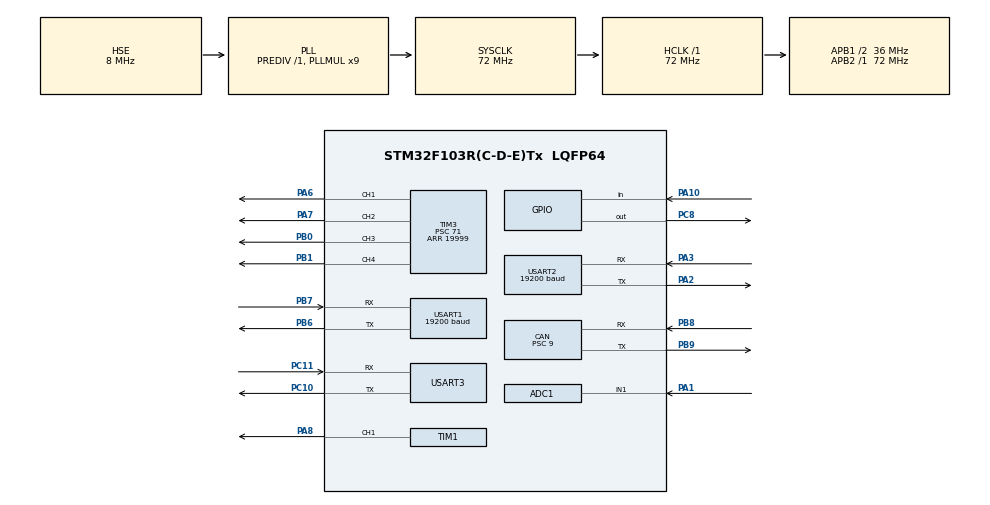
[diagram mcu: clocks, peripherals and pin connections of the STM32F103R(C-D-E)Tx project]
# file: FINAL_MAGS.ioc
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ADC1.Channel-0\#ChannelRegularConversion=ADC_CHANNEL_1
ADC1.ContinuousConvMode=DISABLE
ADC1.DataAlign=ADC_DATAALIGN_RIGHT
ADC1.DiscontinuousConvMode=DISABLE
ADC1.EnableAnalogWatchDog=false
ADC1.EnableRegularConversion=ENABLE
ADC1.ExternalTrigConv=ADC_SOFTWARE_START
ADC1.InjNumberOfConversion=0
ADC1.NbrOfConversion=1
ADC1.NbrOfConversionFlag=1
ADC1.Rank-0\#ChannelRegularConversion=1
ADC1.SamplingTime-0\#ChannelRegularConversion=ADC_SAMPLETIME_239CYCLES_5
ADC1.ScanConvMode=ADC_SCAN_DISABLE
ADC1.master=1
CAN.BS1=CAN_BS1_6TQ
CAN.CalculateTimeBit=750
CAN.CalculateTimeQuantum=250.0
CAN.Prescaler=9
Mcu.Family=STM32F1
Mcu.Name=STM32F103R(C-D-E)Tx
Mcu.Package=LQFP64
NVIC.PriorityGroup=NVIC_PRIORITYGROUP_4
NVIC.TIM7_IRQn=true\:0\:0\:false\:false\:true\:true
NVIC.USART1_IRQn=true\:0\:0\:false\:false\:true\:true
NVIC.USART2_IRQn=true\:0\:0\:false\:false\:true\:true
NVIC.USB_HP_CAN1_TX_IRQn=true\:0\:0\:false\:false\:true\:true
NVIC.USB_LP_CAN1_RX0_IRQn=true\:0\:0\:false\:false\:true\:true
PA1.Signal=ADCx_IN1
PA10.Signal=GPIO_Input
PA2.Mode=Asynchronous
PA2.Signal=USART2_TX
PA3.Mode=Asynchronous
PA3.Signal=USART2_RX
PA6.Signal=S_TIM3_CH1
PA7.Signal=S_TIM3_CH2
PA8.Signal=S_TIM1_CH1
PB0.Signal=S_TIM3_CH3
PB1.Signal=S_TIM3_CH4
PB6.Mode=Asynchronous
PB6.Signal=USART1_TX
PB7.Mode=Asynchronous
PB7.Signal=USART1_RX
PB8.Mode=Master
PB8.Signal=CAN_RX
PB9.Mode=Master
PB9.Signal=CAN_TX
PC10.Mode=Asynchronous
PC10.Signal=USART3_TX
PC11.Mode=Asynchronous
PC11.Signal=USART3_RX
PC8.Signal=GPIO_Output
PD0-OSC_IN.Mode=HSE-External-Oscillator
PD0-OSC_IN.Signal=RCC_OSC_IN
PD1-OSC_OUT.Mode=HSE-External-Oscillator
PD1-OSC_OUT.Signal=RCC_OSC_OUT
ProjectManager.HeapSize=0x200
ProjectManager.StackSize=0x400
ProjectManager.TargetToolchain=EWARM
RCC.ADCPresc=RCC_ADCPCLK2_DIV6
RCC.AHBFreq_Value=72000000
RCC.APB1CLKDivider=RCC_HCLK_DIV2
RCC.APB1Freq_Value=36000000
RCC.APB1TimFreq_Value=72000000
RCC.APB2Freq_Value=72000000
RCC.APB2TimFreq_Value=72000000
RCC.HCLKFreq_Value=72000000
RCC.PLLMUL=RCC_PLL_MUL9
RCC.PLLSourceVirtual=RCC_PLLSOURCE_HSE
RCC.SYSCLKFreq_VALUE=72000000
RCC.SYSCLKSource=RCC_SYSCLKSOURCE_PLLCLK
RCC.USBFreq_Value=72000000
SH.ADCx_IN1.0=ADC1_IN1,IN1
SH.S_TIM1_CH1.0=TIM1_CH1,PWM Generation1 CH1
SH.S_TIM3_CH1.0=TIM3_CH1,PWM Generation1 CH1
SH.S_TIM3_CH2.0=TIM3_CH2,PWM Generation2 CH2
SH.S_TIM3_CH3.0=TIM3_CH3,PWM Generation3 CH3
SH.S_TIM3_CH4.0=TIM3_CH4,PWM Generation4 CH4
TIM1.Channel-PWM\ Generation1\ CH1=TIM_CHANNEL_1
TIM1.Period=19999
TIM1.Prescaler=71
TIM3.Channel-PWM\ Generation1\ CH1=TIM_CHANNEL_1
TIM3.Channel-PWM\ Generation2\ CH2=TIM_CHANNEL_2
TIM3.Channel-PWM\ Generation3\ CH3=TIM_CHANNEL_3
TIM3.Channel-PWM\ Generation4\ CH4=TIM_CHANNEL_4
TIM3.Period=19999
TIM3.Prescaler=71
TIM7.Period=9999
TIM7.Prescaler=7199
USART1.BaudRate=19200
USART1.VirtualMode=VM_ASYNC
USART2.BaudRate=19200
USART2.VirtualMode=VM_ASYNC
USART3.VirtualMode=VM_ASYNC
VP_SYS_VS_ND.Mode=No_Debug
VP_TIM1_VS_ClockSourceINT.Mode=Internal
VP_TIM3_VS_ClockSourceINT.Mode=Internal
VP_TIM7_VS_ClockSourceINT.Mode=Enable_Timer
board=custom

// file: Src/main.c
/**
  ******************************************************************************
  * @file           : main.c
  * @brief          : Main program body
  ******************************************************************************
  ** This notice applies to any and all portions of this file
  * that are not between comment pairs USER CODE BEGIN and
  * USER CODE END. Other portions of this file, whether
  * inserted by the user or by software development tools
  * are owned by their respective copyright owners.
  *
  * COPYRIGHT(c) 2018 STMicroelectronics
  *
  * Redistribution and use in source and binary forms, with or without modification,
  * are permitted provided that the following conditions are met:
  *   1. Redistributions of source code must retain the above copyright notice,
  *      this list of conditions and the following disclaimer.
  *   2. Redistributions in binary form must reproduce the above copyright notice,
  *      this list of conditions and the following disclaimer in the documentation
  *      and/or other materials provided with the distribution.
  *   3. Neither the name of STMicroelectronics nor the names of its contributors
  *      may be used to endorse or promote products derived from this software
  *      without specific prior written permission.
  *
  * THIS SOFTWARE IS PROVIDED BY THE COPYRIGHT HOLDERS AND CONTRIBUTORS "AS IS"
  * AND ANY EXPRESS OR IMPLIED WARRANTIES, INCLUDING, BUT NOT LIMITED TO, THE
  * IMPLIED WARRANTIES OF MERCHANTABILITY AND FITNESS FOR A PARTICULAR PURPOSE ARE
  * DISCLAIMED. IN NO EVENT SHALL THE COPYRIGHT HOLDER OR CONTRIBUTORS BE LIABLE
  * FOR ANY DIRECT, INDIRECT, INCIDENTAL, SPECIAL, EXEMPLARY, OR CONSEQUENTIAL
  * DAMAGES (INCLUDING, BUT NOT LIMITED TO, PROCUREMENT OF SUBSTITUTE GOODS OR
  * SERVICES; LOSS OF USE, DATA, OR PROFITS; OR BUSINESS INTERRUPTION) HOWEVER
  * CAUSED AND ON ANY THEORY OF LIABILITY, WHETHER IN CONTRACT, STRICT LIABILITY,
  * OR TORT (INCLUDING NEGLIGENCE OR OTHERWISE) ARISING IN ANY WAY OUT OF THE USE
  * OF THIS SOFTWARE, EVEN IF ADVISED OF THE POSSIBILITY OF SUCH DAMAGE.
  *
  ******************************************************************************
  */
#include "main.h"
#include "stm32f1xx_hal.h"

/* USER CODE BEGIN Includes */
#include "total.h"
#include <string.h>
#include <stdio.h>
#include <stdlib.h>
#include <math.h>
#define PI 3.141592
/* USER CODE END Includes */

ADC_HandleTypeDef hadc1;

CAN_HandleTypeDef hcan;

TIM_HandleTypeDef htim1;
TIM_HandleTypeDef htim3;
TIM_HandleTypeDef htim7;

UART_HandleTypeDef huart1;
UART_HandleTypeDef huart2;
UART_HandleTypeDef huart3;

/* USER CODE BEGIN PV */
/* Private variables ---------------------------------------------------------*/
uint8_t buffer[1];//store uart1 rf received value
int tim_sec,servo=1500,bat_value;//In timer interrupt variation to update NOW latitude,longtitude;
double Al,Dl,Aa,Da,yaw_1;//GPS_Auto_sailing variation
extern int G_dir,M_spd,M_dir,stop_flag,flag_4,flag_5,flag_6;
double Dlatitude,Dlongtitude;//GPS_Auto_sailing GPS arrive location
extern uint8_t BUF[500];//GPS_BUF
extern uint8_t GPSBUF[500];
extern uint8_t rx_buf[1];

int n = 0;

uint8_t DGPS[19];
uint8_t Dlat[9];
uint8_t Dlong[10];
uint8_t DLAT[9];
uint8_t DLONG[10];
uint8_t tmp[19];
/* USER CODE END PV */

void SystemClock_Config(void);
static void MX_GPIO_Init(void);
static void MX_USART1_UART_Init(void);
static void MX_USART2_UART_Init(void);
static void MX_ADC1_Init(void);
static void MX_TIM3_Init(void);
static void MX_TIM1_Init(void);
static void MX_USART3_UART_Init(void);
static void MX_CAN_Init(void);
static void MX_TIM7_Init(void);

void HAL_TIM_MspPostInit(TIM_HandleTypeDef *htim);

/* USER CODE BEGIN PFP */
/* Private function prototypes -----------------------------------------------*/

/* USER CODE END PFP */

/* USER CODE BEGIN 0 */
int fputc(int ch, FILE *f)
{
    uint8_t temp[1]={ch};

    HAL_UART_Transmit(&huart1, temp, 1, 1000);

  return(ch);
}

void reset_state()
{
        //moter speed step1
        TIM3->CCR3=1575;
        HAL_Delay(10);
        //moter servo center
        TIM3->CCR1=servo;
        HAL_Delay(10);
        //gimbal direction center
        TIM1->CCR1=1500;
        HAL_Delay(10);
        //direction , speed value reset
        G_dir=4;
        M_spd=2;
        M_dir=5;
	servo=1500;
}

void HAL_TIM_PeriodElapsedCallback(TIM_HandleTypeDef *htim)
{
    if(htim->Instance==TIM7)
    {
        if(flag_4==1)
          tim_sec++;

        bat_value++;
        if(bat_value>60)
        {
             bat_value=0;
             Bat_check(&hadc1);
        }
    }
}

/* USER CODE END 0 */

int main(void)
{
  /* USER CODE BEGIN 1 */
  double A_ang,D_ang;
  double error;
  double p_gain=0.3;
  /* USER CODE END 1 */

  /* MCU Configuration----------------------------------------------------------*/

  /* Reset of all peripherals, Initializes the Flash interface and the Systick. */
  HAL_Init();

  /* Configure the system clock */
  SystemClock_Config();

  /* Initialize all configured peripherals */
  MX_GPIO_Init();
  MX_USART1_UART_Init();
  MX_USART2_UART_Init();
  MX_ADC1_Init();
  MX_TIM3_Init();
  MX_TIM1_Init();
  MX_USART3_UART_Init();
  MX_CAN_Init();
  MX_TIM7_Init();
  /* USER CODE BEGIN 2 */
  HAL_TIM_PWM_Start(&htim3,TIM_CHANNEL_3);      //main moter pwm start_TIM3_CH3
  HAL_TIM_PWM_Start(&htim3,TIM_CHANNEL_2);      //water moter pwm start_TIM3_CH2
  HAL_TIM_PWM_Start(&htim3,TIM_CHANNEL_1);      //main servo pwm start_TIM3_CH1
  HAL_TIM_PWM_Start(&htim1,TIM_CHANNEL_1);      //gimbal servo pwm start_TIM1_CH1
  HAL_TIM_Base_Start_IT(&htim7);//tim intrrupt start
  uint8_t p_gain_cont[7]={0,};
  /* USER CODE END 2 */

  /* Infinite loop */
  /* USER CODE BEGIN WHILE */
  while (1)
  {

    HAL_UART_Receive_IT(&huart1,buffer, 1);
    water_mot_con(GPIOA, GPIO_PIN_10);
    if((HAL_UART_Receive(&huart2,tmp,19, 500)==HAL_OK))
    {
      for(int i=0;i<19;i++)
      {
        if(i==2||i==12)
          tmp[i]=tmp[i];
        else
        tmp[i] = tmp[i]-48;
      }
        Da=tmp[0]*10 + tmp[1] + tmp[3]*0.1 + tmp[4]*0.01 + tmp[5]*0.001 + tmp[6]*0.0001 + tmp[7]*0.00001 + tmp[8]*0.000001;
        Dl=tmp[9]*100 + tmp[10]*10 + tmp[11] + tmp[13]*0.1 + tmp[14]*0.01 + tmp[15]*0.001 + tmp[16]*0.0001+ tmp[17]*0.00001 + tmp[18]*0.000001;
        printf("g%lf%lf",Da,Dl);

       for(int i=0;i<19;i++)
      {
        tmp[i] = 0;
      }
    }

    double SD = Yaw_Parse(&huart1,&huart3);

    if(flag_6==1)
    {

        int tmp[7]={0,};
        while(1)
        {
                if((HAL_UART_Receive(&huart1,p_gain_cont, 7, 100000)==HAL_OK))
                {
                    for(int i=0; i<7; i++)
                    {
                      if(i==1)
                        tmp[i]=tmp[i];
                      else
                        tmp[i]=p_gain_cont[i]-48;
                    }
                    p_gain=tmp[0]+tmp[2]*0.1+tmp[3]*0.01+tmp[4]*0.001+tmp[5]*0.0001+tmp[6]*0.00001;
                    flag_6=0;
                    printf("%lf",p_gain);
                    break;
                }
        }
    }
    //receive arrive gps location and start gps chashing
    if(flag_4==1)
      {

        while(1)
        {
                if((HAL_UART_Receive(&huart1, DGPS, 19, 100000)==HAL_OK))
                {
                    for(int i=0;i<9;i++)
                    {
                      Dlat[i] = DGPS[i];
                      DLAT[i] = Dlat[i]-48;
                    }
                    for(int i=0;i<10;i++)
                    {
                      Dlong[i] = DGPS[9+i];
                      DLONG[i] = Dlong[i]-48;
                    }
                      Dlatitude = DLAT[0]*10 + DLAT[1] + DLAT[3]*0.1 + DLAT[4]*0.01 + DLAT[5]*0.001 + DLAT[6]*0.0001 + DLAT[7]*0.00001 + DLAT[8]*0.000001;
                      Dlongtitude = DLONG[0]*100 + DLONG[1]*10 + DLONG[2] + DLONG[4]*0.1 + DLONG[5]*0.01 + DLONG[6]*0.001 + DLONG[7]*0.0001+ DLONG[8]*0.00001 + DLONG[9]*0.000001;
                      break;
                }
        }
            while(1)
            {
              TIM3->CCR3=1550;
              while(1)
              {
                if((HAL_UART_Receive(&huart2,tmp,19, 500)==HAL_OK))
                {
                  for(int i=0;i<19;i++)
                  {
                    if(i==2||i==12)
                      tmp[i]=tmp[i];
                    else
                    tmp[i] = tmp[i]-48;
                  }
                    Da=tmp[0]*10 + tmp[1] + tmp[3]*0.1 + tmp[4]*0.01 + tmp[5]*0.001 + tmp[6]*0.0001 + tmp[7]*0.00001 + tmp[8]*0.000001;
                    Dl=tmp[9]*100 + tmp[10]*10 + tmp[11] + tmp[13]*0.1 + tmp[14]*0.01 + tmp[15]*0.001 + tmp[16]*0.0001+ tmp[17]*0.00001 + tmp[18]*0.000001;
                    printf("g%lf%lf",Da,Dl);

                   for(int i=0;i<19;i++)
                  {
                    tmp[i] = 0;
                  }
                    break;
                }
              }
                Al=Dlongtitude;
                Aa=Dlatitude;
                A_ang=atan2(Al-Dl,Aa-Da)*(double)(180/PI);
                reset_state();
                flag_5=1;

                while(1)
                {
                    HAL_UART_Receive_IT(&huart1,buffer, 1);

                    while(1)
                    {
                        if((HAL_UART_Receive(&huart2,tmp,19, 500)==HAL_OK))
                        {
                          for(int i=0;i<19;i++)
                          {
                            if(i==2||i==12)
                              tmp[i]=tmp[i];
                            else
                            tmp[i] = tmp[i]-48;
                          }
                            Da=tmp[0]*10 + tmp[1] + tmp[3]*0.1 + tmp[4]*0.01 + tmp[5]*0.001 + tmp[6]*0.0001 + tmp[7]*0.00001 + tmp[8]*0.000001;
                            Dl=tmp[9]*100 + tmp[10]*10 + tmp[11] + tmp[13]*0.1 + tmp[14]*0.01 + tmp[15]*0.001 + tmp[16]*0.0001+ tmp[17]*0.00001 + tmp[18]*0.000001;
                            printf("g%lf%lf",Da,Dl);
                           for(int i=0;i<19;i++)
                          {
                            tmp[i] = 0;
                          }
                          break;
                        }
                    }

                    if(tim_sec>=3)
                    {
                      A_ang=atan2(Al-Dl,Aa-Da)*(double)(180/PI);
                      tim_sec=0;
                    }

                    D_ang=Yaw_Parse(&huart1,&huart3);
                    error=A_ang-D_ang;
                    error=error*p_gain;
                    //Convert to Min Angle
                    if(error<=-180)
                        error+=360;
                    else if(error>180)
                        error-=360;
                    //servo timer value must integer
                    servo=(int)(servo+10*error);
                    //limit servo degree value
                    if(servo>=1990)
                    {
                        servo=1990;
                        TIM3->CCR1=1990;
                    }
                    else if(servo<=1010)
                    {
                        servo=1010;
                        TIM3->CCR1=1010;
                    }
                    else
                        TIM3->CCR1=servo;
                    //distance a from d
                    if(((fabs(Al-Dl)<=0.0001)&&(fabs(Aa-Da)<=0.0001))||(stop_flag!=0))//오차값 정하고 1대신 넣기
                    {
                        break;
                    }
                }
                flag_5=0;
                reset_state();
                stop_flag=0;
                flag_4=0;
                break;
            }
  /* USER CODE END WHILE */
  }
  }
}

void SystemClock_Config(void)
{

  RCC_OscInitTypeDef RCC_OscInitStruct;
  RCC_ClkInitTypeDef RCC_ClkInitStruct;
  RCC_PeriphCLKInitTypeDef PeriphClkInit;

    /**Initializes the CPU, AHB and APB busses clocks
    */
  RCC_OscInitStruct.OscillatorType = RCC_OSCILLATORTYPE_HSE;
  RCC_OscInitStruct.HSEState = RCC_HSE_ON;
  RCC_OscInitStruct.HSEPredivValue = RCC_HSE_PREDIV_DIV1;
  RCC_OscInitStruct.HSIState = RCC_HSI_ON;
  RCC_OscInitStruct.PLL.PLLState = RCC_PLL_ON;
  RCC_OscInitStruct.PLL.PLLSource = RCC_PLLSOURCE_HSE;
  RCC_OscInitStruct.PLL.PLLMUL = RCC_PLL_MUL9;
  if (HAL_RCC_OscConfig(&RCC_OscInitStruct) != HAL_OK)
  {
    _Error_Handler(__FILE__, __LINE__);
  }

    /**Initializes the CPU, AHB and APB busses clocks
    */
  RCC_ClkInitStruct.ClockType = RCC_CLOCKTYPE_HCLK|RCC_CLOCKTYPE_SYSCLK
                              |RCC_CLOCKTYPE_PCLK1|RCC_CLOCKTYPE_PCLK2;
  RCC_ClkInitStruct.SYSCLKSource = RCC_SYSCLKSOURCE_PLLCLK;
  RCC_ClkInitStruct.AHBCLKDivider = RCC_SYSCLK_DIV1;
  RCC_ClkInitStruct.APB1CLKDivider = RCC_HCLK_DIV2;
  RCC_ClkInitStruct.APB2CLKDivider = RCC_HCLK_DIV1;

  if (HAL_RCC_ClockConfig(&RCC_ClkInitStruct, FLASH_LATENCY_2) != HAL_OK)
  {
    _Error_Handler(__FILE__, __LINE__);
  }

  PeriphClkInit.PeriphClockSelection = RCC_PERIPHCLK_ADC;
  PeriphClkInit.AdcClockSelection = RCC_ADCPCLK2_DIV6;
  if (HAL_RCCEx_PeriphCLKConfig(&PeriphClkInit) != HAL_OK)
  {
    _Error_Handler(__FILE__, __LINE__);
  }

    /**Configure the Systick interrupt time
    */
  HAL_SYSTICK_Config(HAL_RCC_GetHCLKFreq()/1000);

    /**Configure the Systick
    */
  HAL_SYSTICK_CLKSourceConfig(SYSTICK_CLKSOURCE_HCLK);

  /* SysTick_IRQn interrupt configuration */
  HAL_NVIC_SetPriority(SysTick_IRQn, 0, 0);
}

/* ADC1 init function */
static void MX_ADC1_Init(void)
{

  ADC_ChannelConfTypeDef sConfig;

    /**Common config
    */
  hadc1.Instance = ADC1;
  hadc1.Init.ScanConvMode = ADC_SCAN_DISABLE;
  hadc1.Init.ContinuousConvMode = DISABLE;
  hadc1.Init.DiscontinuousConvMode = DISABLE;
  hadc1.Init.ExternalTrigConv = ADC_SOFTWARE_START;
  hadc1.Init.DataAlign = ADC_DATAALIGN_RIGHT;
  hadc1.Init.NbrOfConversion = 1;
  if (HAL_ADC_Init(&hadc1) != HAL_OK)
  {
    _Error_Handler(__FILE__, __LINE__);
  }

    /**Configure Regular Channel
    */
  sConfig.Channel = ADC_CHANNEL_1;
  sConfig.Rank = ADC_REGULAR_RANK_1;
  sConfig.SamplingTime = ADC_SAMPLETIME_239CYCLES_5;
  if (HAL_ADC_ConfigChannel(&hadc1, &sConfig) != HAL_OK)
  {
    _Error_Handler(__FILE__, __LINE__);
  }

}

/* CAN init function */
static void MX_CAN_Init(void)
{

  hcan.Instance = CAN1;
  hcan.Init.Prescaler = 9;
  hcan.Init.Mode = CAN_MODE_NORMAL;
  hcan.Init.SJW = CAN_SJW_1TQ;
  hcan.Init.BS1 = CAN_BS1_6TQ;
  hcan.Init.BS2 = CAN_BS2_1TQ;
  hcan.Init.TTCM = DISABLE;
  hcan.Init.ABOM = DISABLE;
  hcan.Init.AWUM = DISABLE;
  hcan.Init.NART = DISABLE;
  hcan.Init.RFLM = DISABLE;
  hcan.Init.TXFP = DISABLE;
  if (HAL_CAN_Init(&hcan) != HAL_OK)
  {
    _Error_Handler(__FILE__, __LINE__);
  }

}

/* TIM1 init function */
static void MX_TIM1_Init(void)
{

  TIM_ClockConfigTypeDef sClockSourceConfig;
  TIM_MasterConfigTypeDef sMasterConfig;
  TIM_OC_InitTypeDef sConfigOC;
  TIM_BreakDeadTimeConfigTypeDef sBreakDeadTimeConfig;

  htim1.Instance = TIM1;
  htim1.Init.Prescaler = 71;
  htim1.Init.CounterMode = TIM_COUNTERMODE_UP;
  htim1.Init.Period = 19999;
  htim1.Init.ClockDivision = TIM_CLOCKDIVISION_DIV1;
  htim1.Init.RepetitionCounter = 0;
  htim1.Init.AutoReloadPreload = TIM_AUTORELOAD_PRELOAD_DISABLE;
  if (HAL_TIM_Base_Init(&htim1) != HAL_OK)
  {
    _Error_Handler(__FILE__, __LINE__);
  }

  sClockSourceConfig.ClockSource = TIM_CLOCKSOURCE_INTERNAL;
  if (HAL_TIM_ConfigClockSource(&htim1, &sClockSourceConfig) != HAL_OK)
  {
    _Error_Handler(__FILE__, __LINE__);
  }

  if (HAL_TIM_PWM_Init(&htim1) != HAL_OK)
  {
    _Error_Handler(__FILE__, __LINE__);
  }

  sMasterConfig.MasterOutputTrigger = TIM_TRGO_RESET;
  sMasterConfig.MasterSlaveMode = TIM_MASTERSLAVEMODE_DISABLE;
  if (HAL_TIMEx_MasterConfigSynchronization(&htim1, &sMasterConfig) != HAL_OK)
  {
    _Error_Handler(__FILE__, __LINE__);
  }

  sConfigOC.OCMode = TIM_OCMODE_PWM1;
  sConfigOC.Pulse = 0;
  sConfigOC.OCPolarity = TIM_OCPOLARITY_HIGH;
  sConfigOC.OCNPolarity = TIM_OCNPOLARITY_HIGH;
  sConfigOC.OCFastMode = TIM_OCFAST_DISABLE;
  sConfigOC.OCIdleState = TIM_OCIDLESTATE_RESET;
  sConfigOC.OCNIdleState = TIM_OCNIDLESTATE_RESET;
  if (HAL_TIM_PWM_ConfigChannel(&htim1, &sConfigOC, TIM_CHANNEL_1) != HAL_OK)
  {
    _Error_Handler(__FILE__, __LINE__);
  }

  sBreakDeadTimeConfig.OffStateRunMode = TIM_OSSR_DISABLE;
  sBreakDeadTimeConfig.OffStateIDLEMode = TIM_OSSI_DISABLE;
  sBreakDeadTimeConfig.LockLevel = TIM_LOCKLEVEL_OFF;
  sBreakDeadTimeConfig.DeadTime = 0;
  sBreakDeadTimeConfig.BreakState = TIM_BREAK_DISABLE;
  sBreakDeadTimeConfig.BreakPolarity = TIM_BREAKPOLARITY_HIGH;
  sBreakDeadTimeConfig.AutomaticOutput = TIM_AUTOMATICOUTPUT_DISABLE;
  if (HAL_TIMEx_ConfigBreakDeadTime(&htim1, &sBreakDeadTimeConfig) != HAL_OK)
  {
    _Error_Handler(__FILE__, __LINE__);
  }

  HAL_TIM_MspPostInit(&htim1);

}

/* TIM3 init function */
static void MX_TIM3_Init(void)
{

  TIM_ClockConfigTypeDef sClockSourceConfig;
  TIM_MasterConfigTypeDef sMasterConfig;
  TIM_OC_InitTypeDef sConfigOC;

  htim3.Instance = TIM3;
  htim3.Init.Prescaler = 71;
  htim3.Init.CounterMode = TIM_COUNTERMODE_UP;
  htim3.Init.Period = 19999;
  htim3.Init.ClockDivision = TIM_CLOCKDIVISION_DIV1;
  htim3.Init.AutoReloadPreload = TIM_AUTORELOAD_PRELOAD_DISABLE;
  if (HAL_TIM_Base_Init(&htim3) != HAL_OK)
  {
    _Error_Handler(__FILE__, __LINE__);
  }

  sClockSourceConfig.ClockSource = TIM_CLOCKSOURCE_INTERNAL;
  if (HAL_TIM_ConfigClockSource(&htim3, &sClockSourceConfig) != HAL_OK)
  {
    _Error_Handler(__FILE__, __LINE__);
  }

  if (HAL_TIM_PWM_Init(&htim3) != HAL_OK)
  {
    _Error_Handler(__FILE__, __LINE__);
  }

  sMasterConfig.MasterOutputTrigger = TIM_TRGO_RESET;
  sMasterConfig.MasterSlaveMode = TIM_MASTERSLAVEMODE_DISABLE;
  if (HAL_TIMEx_MasterConfigSynchronization(&htim3, &sMasterConfig) != HAL_OK)
  {
    _Error_Handler(__FILE__, __LINE__);
  }

  sConfigOC.OCMode = TIM_OCMODE_PWM1;
  sConfigOC.Pulse = 0;
  sConfigOC.OCPolarity = TIM_OCPOLARITY_HIGH;
  sConfigOC.OCFastMode = TIM_OCFAST_DISABLE;
  if (HAL_TIM_PWM_ConfigChannel(&htim3, &sConfigOC, TIM_CHANNEL_1) != HAL_OK)
  {
    _Error_Handler(__FILE__, __LINE__);
  }

  if (HAL_TIM_PWM_ConfigChannel(&htim3, &sConfigOC, TIM_CHANNEL_2) != HAL_OK)
  {
    _Error_Handler(__FILE__, __LINE__);
  }

  if (HAL_TIM_PWM_ConfigChannel(&htim3, &sConfigOC, TIM_CHANNEL_3) != HAL_OK)
  {
    _Error_Handler(__FILE__, __LINE__);
  }

  if (HAL_TIM_PWM_ConfigChannel(&htim3, &sConfigOC, TIM_CHANNEL_4) != HAL_OK)
  {
    _Error_Handler(__FILE__, __LINE__);
  }

  HAL_TIM_MspPostInit(&htim3);

}

/* TIM7 init function */
static void MX_TIM7_Init(void)
{

  TIM_MasterConfigTypeDef sMasterConfig;

  htim7.Instance = TIM7;
  htim7.Init.Prescaler = 7199;
  htim7.Init.CounterMode = TIM_COUNTERMODE_UP;
  htim7.Init.Period = 9999;
  htim7.Init.AutoReloadPreload = TIM_AUTORELOAD_PRELOAD_DISABLE;
  if (HAL_TIM_Base_Init(&htim7) != HAL_OK)
  {
    _Error_Handler(__FILE__, __LINE__);
  }

  sMasterConfig.MasterOutputTrigger = TIM_TRGO_RESET;
  sMasterConfig.MasterSlaveMode = TIM_MASTERSLAVEMODE_DISABLE;
  if (HAL_TIMEx_MasterConfigSynchronization(&htim7, &sMasterConfig) != HAL_OK)
  {
    _Error_Handler(__FILE__, __LINE__);
  }

}

/* USART1 init function */
static void MX_USART1_UART_Init(void)
{

  huart1.Instance = USART1;
  huart1.Init.BaudRate = 19200;
  huart1.Init.WordLength = UART_WORDLENGTH_8B;
  huart1.Init.StopBits = UART_STOPBITS_1;
  huart1.Init.Parity = UART_PARITY_NONE;
  huart1.Init.Mode = UART_MODE_TX_RX;
  huart1.Init.HwFlowCtl = UART_HWCONTROL_NONE;
  huart1.Init.OverSampling = UART_OVERSAMPLING_16;
  if (HAL_UART_Init(&huart1) != HAL_OK)
  {
    _Error_Handler(__FILE__, __LINE__);
  }

}

/* USART2 init function */
static void MX_USART2_UART_Init(void)
{

  huart2.Instance = USART2;
  huart2.Init.BaudRate = 19200;
  huart2.Init.WordLength = UART_WORDLENGTH_8B;
  huart2.Init.StopBits = UART_STOPBITS_1;
  huart2.Init.Parity = UART_PARITY_NONE;
  huart2.Init.Mode = UART_MODE_TX_RX;
  huart2.Init.HwFlowCtl = UART_HWCONTROL_NONE;
  huart2.Init.OverSampling = UART_OVERSAMPLING_16;
  if (HAL_UART_Init(&huart2) != HAL_OK)
  {
    _Error_Handler(__FILE__, __LINE__);
  }

}

/* USART3 init function */
static void MX_USART3_UART_Init(void)
{

  huart3.Instance = USART3;
  huart3.Init.BaudRate = 115200;
  huart3.Init.WordLength = UART_WORDLENGTH_8B;
  huart3.Init.StopBits = UART_STOPBITS_1;
  huart3.Init.Parity = UART_PARITY_NONE;
  huart3.Init.Mode = UART_MODE_TX_RX;
  huart3.Init.HwFlowCtl = UART_HWCONTROL_NONE;
  huart3.Init.OverSampling = UART_OVERSAMPLING_16;
  if (HAL_UART_Init(&huart3) != HAL_OK)
  {
    _Error_Handler(__FILE__, __LINE__);
  }

}

/** Configure pins as
        * Analog
        * Input
        * Output
        * EVENT_OUT
        * EXTI
*/
static void MX_GPIO_Init(void)
{

  GPIO_InitTypeDef GPIO_InitStruct;

  /* GPIO Ports Clock Enable */
  __HAL_RCC_GPIOD_CLK_ENABLE();
  __HAL_RCC_GPIOA_CLK_ENABLE();
  __HAL_RCC_GPIOB_CLK_ENABLE();
  __HAL_RCC_GPIOC_CLK_ENABLE();

  /*Configure GPIO pin Output Level */
  HAL_GPIO_WritePin(GPIOC, GPIO_PIN_8, GPIO_PIN_RESET);

  /*Configure GPIO pin : PC8 */
  GPIO_InitStruct.Pin = GPIO_PIN_8;
  GPIO_InitStruct.Mode = GPIO_MODE_OUTPUT_PP;
  GPIO_InitStruct.Pull = GPIO_NOPULL;
  GPIO_InitStruct.Speed = GPIO_SPEED_FREQ_LOW;
  HAL_GPIO_Init(GPIOC, &GPIO_InitStruct);

  /*Configure GPIO pin : PA10 */
  GPIO_InitStruct.Pin = GPIO_PIN_10;
  GPIO_InitStruct.Mode = GPIO_MODE_INPUT;
  GPIO_InitStruct.Pull = GPIO_NOPULL;
  HAL_GPIO_Init(GPIOA, &GPIO_InitStruct);

}

void _Error_Handler(char *file, int line)
{
  while(1)
  {
  }
}

/************************ (C) COPYRIGHT STMicroelectronics *****END OF FILE****/
